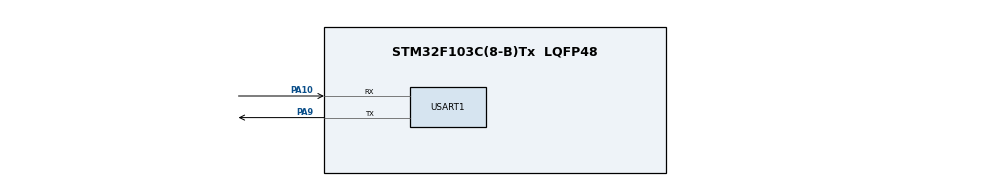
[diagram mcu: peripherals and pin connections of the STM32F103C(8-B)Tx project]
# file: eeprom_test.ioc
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Mcu.Family=STM32F1
Mcu.Name=STM32F103C(8-B)Tx
Mcu.Package=LQFP48
NVIC.PriorityGroup=NVIC_PRIORITYGROUP_4
PA10.Mode=Asynchronous
PA10.Signal=USART1_RX
PA13.Mode=Serial_Wire
PA13.Signal=SYS_JTMS-SWDIO
PA14.Mode=Serial_Wire
PA14.Signal=SYS_JTCK-SWCLK
PA9.Mode=Asynchronous
PA9.Signal=USART1_TX
ProjectManager.HeapSize=0x200
ProjectManager.StackSize=0x400
ProjectManager.TargetToolchain=MDK-ARM V5.32
RCC.APB1Freq_Value=8000000
RCC.APB2Freq_Value=8000000
USART1.VirtualMode=VM_ASYNC
board=custom

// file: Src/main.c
/* USER CODE BEGIN Header */
/**
  ******************************************************************************
  * @file           : main.c
  * @brief          : Main program body
  ******************************************************************************
  * @attention
  *
  * Copyright (c) 2021 STMicroelectronics.
  * All rights reserved.
  *
  * This software is licensed under terms that can be found in the LICENSE file
  * in the root directory of this software component.
  * If no LICENSE file comes with this software, it is provided AS-IS.
  *
  ******************************************************************************
  */
/* USER CODE END Header */
#include "main.h"

/* USER CODE BEGIN Includes */
#include "eeprom_in_flash.h"
/* USER CODE END Includes */

/* USER CODE BEGIN PTD */
#pragma pack(1)
typedef struct
{
	uint32_t boot_count;	//0
	uint16_t modbus_addr;	//4

	int32_t Voltage_offset;	//6
	int32_t Current_offset;	//10
}Config_type;
#pragma pack()
/* USER CODE END PTD */

/* USER CODE BEGIN PD */
int fputc(int ch, FILE *f)
{
	while((USART1->SR&0X40)==0){}
    USART1->DR = (uint8_t) ch;
	return ch;
}
/* USER CODE END PD */

UART_HandleTypeDef huart1;

/* USER CODE BEGIN PV */
const Config_type Config_default = {
	.boot_count = 0,
	.modbus_addr = 1,
	.Voltage_offset = 3000,
	.Current_offset = -2000,
};
/* USER CODE END PV */

void SystemClock_Config(void);
static void MX_GPIO_Init(void);
static void MX_USART1_UART_Init(void);

int main(void)
{

  /* MCU Configuration--------------------------------------------------------*/

  /* Reset of all peripherals, Initializes the Flash interface and the Systick. */
  HAL_Init();

  /* Configure the system clock */
  SystemClock_Config();

  /* Initialize all configured peripherals */
  MX_GPIO_Init();
  MX_USART1_UART_Init();
  /* USER CODE BEGIN 2 */
	log_printf(LOG_Assert, "system start!\r\n");

	EEPROM_Init((void *)&Config_default);

	uint32_t boot_count = 0;
	Config_Read_Buf(0, &boot_count, sizeof(boot_count));
	boot_count++;
	Config_Write_Buf(0, &boot_count, sizeof(boot_count));
	log_printf(LOG_Info, "----------> system boot count: %d\r\n\r\n", boot_count);

  /* USER CODE END 2 */

  /* Infinite loop */
  /* USER CODE BEGIN WHILE */
	uint32_t Voltage;
	Config_Read_Buf(6, &Voltage, sizeof(Voltage));
  while (1)
  {
		HAL_Delay(2000);

		Config_Read_Buf(6, &Voltage, sizeof(Voltage));
		log_printf(LOG_Debug, "----------> Read Voltage_offset is %d\r\n", Voltage);

		HAL_Delay(500);

		log_printf(LOG_Debug, "----------> change Voltage %d to %d\r\n", Voltage, Voltage+20);
		Voltage += 20;
		Config_Write_Buf(6, &Voltage, sizeof(Voltage));

		if(Voltage > 3400)
		{
			log_printf(LOG_Debug, "----------> Format eeprom with default data\r\n");
			EEPROM_Format((void *)&Config_default);
		}
    /* USER CODE END WHILE */

  }
}

void SystemClock_Config(void)
{
  RCC_OscInitTypeDef RCC_OscInitStruct = {0};
  RCC_ClkInitTypeDef RCC_ClkInitStruct = {0};

  /** Initializes the RCC Oscillators according to the specified parameters
  * in the RCC_OscInitTypeDef structure.
  */
  RCC_OscInitStruct.OscillatorType = RCC_OSCILLATORTYPE_HSI;
  RCC_OscInitStruct.HSIState = RCC_HSI_ON;
  RCC_OscInitStruct.HSICalibrationValue = RCC_HSICALIBRATION_DEFAULT;
  RCC_OscInitStruct.PLL.PLLState = RCC_PLL_NONE;
  if (HAL_RCC_OscConfig(&RCC_OscInitStruct) != HAL_OK)
  {
    Error_Handler();
  }
  /** Initializes the CPU, AHB and APB buses clocks
  */
  RCC_ClkInitStruct.ClockType = RCC_CLOCKTYPE_HCLK|RCC_CLOCKTYPE_SYSCLK
                              |RCC_CLOCKTYPE_PCLK1|RCC_CLOCKTYPE_PCLK2;
  RCC_ClkInitStruct.SYSCLKSource = RCC_SYSCLKSOURCE_HSI;
  RCC_ClkInitStruct.AHBCLKDivider = RCC_SYSCLK_DIV1;
  RCC_ClkInitStruct.APB1CLKDivider = RCC_HCLK_DIV1;
  RCC_ClkInitStruct.APB2CLKDivider = RCC_HCLK_DIV1;

  if (HAL_RCC_ClockConfig(&RCC_ClkInitStruct, FLASH_LATENCY_0) != HAL_OK)
  {
    Error_Handler();
  }
}

static void MX_USART1_UART_Init(void)
{

  huart1.Instance = USART1;
  huart1.Init.BaudRate = 115200;
  huart1.Init.WordLength = UART_WORDLENGTH_8B;
  huart1.Init.StopBits = UART_STOPBITS_1;
  huart1.Init.Parity = UART_PARITY_NONE;
  huart1.Init.Mode = UART_MODE_TX_RX;
  huart1.Init.HwFlowCtl = UART_HWCONTROL_NONE;
  huart1.Init.OverSampling = UART_OVERSAMPLING_16;
  if (HAL_UART_Init(&huart1) != HAL_OK)
  {
    Error_Handler();
  }

}

static void MX_GPIO_Init(void)
{

  /* GPIO Ports Clock Enable */
  __HAL_RCC_GPIOA_CLK_ENABLE();

}

void Error_Handler(void)
{
  __disable_irq();
  while (1)
  {
  }
}
